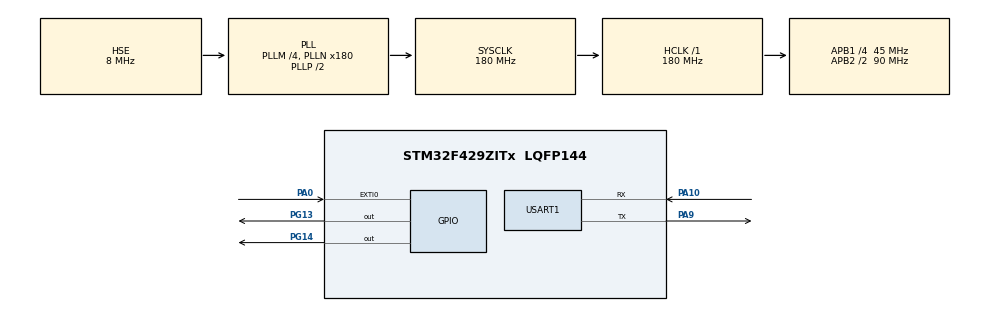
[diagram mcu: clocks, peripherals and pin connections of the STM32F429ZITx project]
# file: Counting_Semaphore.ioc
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FREERTOS.Tasks01=defaultTask,0,128,StartDefaultTask,Default,NULL,Dynamic,NULL,NULL
FREERTOS.configUSE_COUNTING_SEMAPHORES=1
Mcu.Family=STM32F4
Mcu.Name=STM32F429ZITx
Mcu.Package=LQFP144
NVIC.EXTI0_IRQn=true\:5\:0\:false\:false\:true\:true\:true\:true\:true
NVIC.PriorityGroup=NVIC_PRIORITYGROUP_4
NVIC.TIM6_DAC_IRQn=true\:15\:0\:false\:false\:true\:false\:false\:true\:true
NVIC.TimeBase=TIM6_DAC_IRQn
NVIC.TimeBaseIP=TIM6
PA0/WKUP.Signal=GPXTI0
PA10.Mode=Asynchronous
PA10.Signal=USART1_RX
PA9.Mode=Asynchronous
PA9.Signal=USART1_TX
PG13.Signal=GPIO_Output
PG14.Signal=GPIO_Output
PH0/OSC_IN.Mode=HSE-External-Oscillator
PH0/OSC_IN.Signal=RCC_OSC_IN
PH1/OSC_OUT.Mode=HSE-External-Oscillator
PH1/OSC_OUT.Signal=RCC_OSC_OUT
ProjectManager.HeapSize=0x200
ProjectManager.StackSize=0x400
ProjectManager.TargetToolchain=STM32CubeIDE
RCC.48MHZClocksFreq_Value=51428571.428571425
RCC.AHBFreq_Value=180000000
RCC.APB1CLKDivider=RCC_HCLK_DIV4
RCC.APB1Freq_Value=45000000
RCC.APB1TimFreq_Value=90000000
RCC.APB2CLKDivider=RCC_HCLK_DIV2
RCC.APB2Freq_Value=90000000
RCC.APB2TimFreq_Value=180000000
RCC.CortexFreq_Value=180000000
RCC.HCLKFreq_Value=180000000
RCC.HSE_VALUE=8000000
RCC.HSI_VALUE=16000000
RCC.LSE_VALUE=32768
RCC.PLLM=4
RCC.PLLN=180
RCC.PLLQ=7
RCC.PLLSourceVirtual=RCC_PLLSOURCE_HSE
RCC.SYSCLKFreq_VALUE=180000000
RCC.SYSCLKSource=RCC_SYSCLKSOURCE_PLLCLK
RCC.VCOOutputFreq_Value=360000000
USART1.VirtualMode=VM_ASYNC
VP_FREERTOS_VS_CMSIS_V1.Mode=CMSIS_V1
VP_SYS_VS_tim6.Mode=TIM6
board=STM32F429I-DISC1

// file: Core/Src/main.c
/* USER CODE BEGIN Header */
/**
  ******************************************************************************
  * @file           : main.c
  * @brief          : Main program body
  ******************************************************************************
  * @attention
  *
  * Copyright (c) 2025 STMicroelectronics.
  * All rights reserved.
  *
  * This software is licensed under terms that can be found in the LICENSE file
  * in the root directory of this software component.
  * If no LICENSE file comes with this software, it is provided AS-IS.
  *
  ******************************************************************************
  */
/* USER CODE END Header */
#include "main.h"
#include "FreeRTOS.h"
#include "task.h"
#include "timers.h"
#include "queue.h"
#include "semphr.h"
#include "event_groups.h"

UART_HandleTypeDef huart1;

void SystemClock_Config(void);
static void MX_GPIO_Init(void);
static void MX_USART1_UART_Init(void);

/* USER CODE BEGIN 0 */

TaskHandle_t Task01_Handle;
TaskHandle_t Task02_Handle;
TaskHandle_t Task03_Handle;

SemaphoreHandle_t CountingSemaphore_Handle;

void Task01(void* arg)
{
	while(1)
	{
		HAL_GPIO_TogglePin(GPIOG, GPIO_PIN_11);
		vTaskDelay(pdMS_TO_TICKS(500));
	}
}

void Task02(void* arg)
{
	xSemaphoreGive(CountingSemaphore_Handle);
	xSemaphoreGive(CountingSemaphore_Handle);
	while(1)
	{
		xSemaphoreTake(CountingSemaphore_Handle, portMAX_DELAY);

		HAL_GPIO_WritePin(GPIOG, GPIO_PIN_13, GPIO_PIN_SET);

		vTaskDelay(pdMS_TO_TICKS(1000));

		HAL_GPIO_WritePin(GPIOG, GPIO_PIN_13, GPIO_PIN_RESET);
	}
}

void Task03(void* arg)
{
	while(1)
	{
		xSemaphoreTake(CountingSemaphore_Handle, portMAX_DELAY);

		HAL_GPIO_WritePin(GPIOG, GPIO_PIN_14, GPIO_PIN_SET);

		vTaskDelay(pdMS_TO_TICKS(1000));

		HAL_GPIO_WritePin(GPIOG, GPIO_PIN_14, GPIO_PIN_RESET);
	}
}

void HAL_GPIO_EXTI_Callback(uint16_t GPIO_Pin)
{
  if(GPIO_Pin == GPIO_PIN_0)
  {

	  // Release the binary semaphore
	  BaseType_t xHigherPriorityTaskWoken = pdFALSE;
	  xSemaphoreGiveFromISR(CountingSemaphore_Handle, &xHigherPriorityTaskWoken);

	  // Perform context switch if needed
	  portEND_SWITCHING_ISR(xHigherPriorityTaskWoken);

  }
}

/* USER CODE END 0 */

int main(void)
{

  /* MCU Configuration--------------------------------------------------------*/

  /* Reset of all peripherals, Initializes the Flash interface and the Systick. */
  HAL_Init();

  /* Configure the system clock */
  SystemClock_Config();

  /* Initialize all configured peripherals */
  MX_GPIO_Init();
  MX_USART1_UART_Init();
  /* USER CODE BEGIN 2 */

  CountingSemaphore_Handle = xSemaphoreCreateCounting(2,0);
  if(CountingSemaphore_Handle == NULL) HAL_UART_Transmit(&huart1,(uint8_t *) "Unable to create semaphore\n\n",29, 100);
  else HAL_UART_Transmit(&huart1,(uint8_t *) "Counting Semaphore created successfully\n\n", 42, 100);

  xTaskCreate(Task01, "T1", 128, NULL, 3, &Task01_Handle);
  xTaskCreate(Task02, "T2", 128, NULL, 2, &Task02_Handle);
  xTaskCreate(Task03, "T3", 128, NULL, 1, &Task03_Handle);

  vTaskStartScheduler();

  /* USER CODE END 2 */

  /* We should never get here as control is now taken by the scheduler */

  /* Infinite loop */
  while (1)
  {

  }
}

void SystemClock_Config(void)
{
  RCC_OscInitTypeDef RCC_OscInitStruct = {0};
  RCC_ClkInitTypeDef RCC_ClkInitStruct = {0};

  /** Configure the main internal regulator output voltage
  */
  __HAL_RCC_PWR_CLK_ENABLE();
  __HAL_PWR_VOLTAGESCALING_CONFIG(PWR_REGULATOR_VOLTAGE_SCALE1);

  /** Initializes the RCC Oscillators according to the specified parameters
  * in the RCC_OscInitTypeDef structure.
  */
  RCC_OscInitStruct.OscillatorType = RCC_OSCILLATORTYPE_HSE;
  RCC_OscInitStruct.HSEState = RCC_HSE_ON;
  RCC_OscInitStruct.PLL.PLLState = RCC_PLL_ON;
  RCC_OscInitStruct.PLL.PLLSource = RCC_PLLSOURCE_HSE;
  RCC_OscInitStruct.PLL.PLLM = 4;
  RCC_OscInitStruct.PLL.PLLN = 180;
  RCC_OscInitStruct.PLL.PLLP = RCC_PLLP_DIV2;
  RCC_OscInitStruct.PLL.PLLQ = 7;
  if (HAL_RCC_OscConfig(&RCC_OscInitStruct) != HAL_OK)
  {
    Error_Handler();
  }

  /** Activate the Over-Drive mode
  */
  if (HAL_PWREx_EnableOverDrive() != HAL_OK)
  {
    Error_Handler();
  }

  /** Initializes the CPU, AHB and APB buses clocks
  */
  RCC_ClkInitStruct.ClockType = RCC_CLOCKTYPE_HCLK|RCC_CLOCKTYPE_SYSCLK
                              |RCC_CLOCKTYPE_PCLK1|RCC_CLOCKTYPE_PCLK2;
  RCC_ClkInitStruct.SYSCLKSource = RCC_SYSCLKSOURCE_PLLCLK;
  RCC_ClkInitStruct.AHBCLKDivider = RCC_SYSCLK_DIV1;
  RCC_ClkInitStruct.APB1CLKDivider = RCC_HCLK_DIV4;
  RCC_ClkInitStruct.APB2CLKDivider = RCC_HCLK_DIV2;

  if (HAL_RCC_ClockConfig(&RCC_ClkInitStruct, FLASH_LATENCY_5) != HAL_OK)
  {
    Error_Handler();
  }
}

static void MX_USART1_UART_Init(void)
{

  huart1.Instance = USART1;
  huart1.Init.BaudRate = 115200;
  huart1.Init.WordLength = UART_WORDLENGTH_8B;
  huart1.Init.StopBits = UART_STOPBITS_1;
  huart1.Init.Parity = UART_PARITY_NONE;
  huart1.Init.Mode = UART_MODE_TX_RX;
  huart1.Init.HwFlowCtl = UART_HWCONTROL_NONE;
  huart1.Init.OverSampling = UART_OVERSAMPLING_16;
  if (HAL_UART_Init(&huart1) != HAL_OK)
  {
    Error_Handler();
  }

}

static void MX_GPIO_Init(void)
{
  GPIO_InitTypeDef GPIO_InitStruct = {0};

  /* GPIO Ports Clock Enable */
  __HAL_RCC_GPIOH_CLK_ENABLE();
  __HAL_RCC_GPIOA_CLK_ENABLE();
  __HAL_RCC_GPIOG_CLK_ENABLE();

  /*Configure GPIO pin Output Level */
  HAL_GPIO_WritePin(GPIOG, GPIO_PIN_11 | GPIO_PIN_13|GPIO_PIN_14, GPIO_PIN_RESET);

  /*Configure GPIO pin : PA0 */
  GPIO_InitStruct.Pin = GPIO_PIN_0;
  GPIO_InitStruct.Mode = GPIO_MODE_IT_RISING;
  GPIO_InitStruct.Pull = GPIO_NOPULL;
  HAL_GPIO_Init(GPIOA, &GPIO_InitStruct);

  /*Configure GPIO pins : PG13 PG14 */
  GPIO_InitStruct.Pin = GPIO_PIN_11|GPIO_PIN_13|GPIO_PIN_14;
  GPIO_InitStruct.Mode = GPIO_MODE_OUTPUT_PP;
  GPIO_InitStruct.Pull = GPIO_NOPULL;
  GPIO_InitStruct.Speed = GPIO_SPEED_FREQ_LOW;
  HAL_GPIO_Init(GPIOG, &GPIO_InitStruct);

  /* EXTI interrupt init*/
  HAL_NVIC_SetPriority(EXTI0_IRQn, 7, 0);
  HAL_NVIC_EnableIRQ(EXTI0_IRQn);

}

void HAL_TIM_PeriodElapsedCallback(TIM_HandleTypeDef *htim)
{
  if (htim->Instance == TIM6)
  {
    HAL_IncTick();
  }
}

void Error_Handler(void)
{
  __disable_irq();
  while (1)
  {
  }
}
